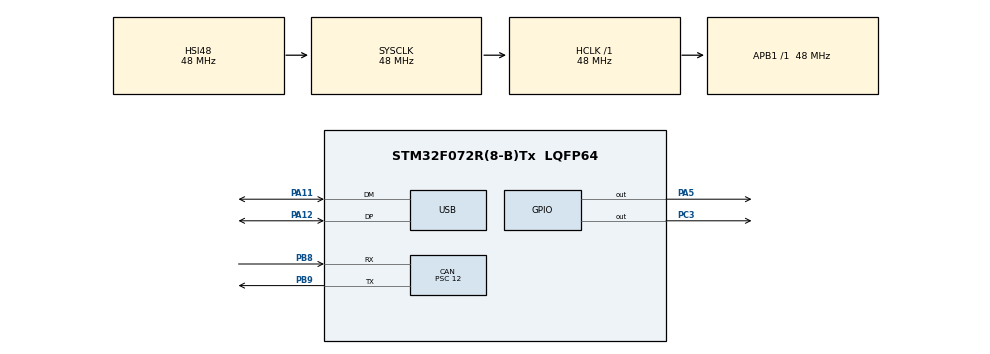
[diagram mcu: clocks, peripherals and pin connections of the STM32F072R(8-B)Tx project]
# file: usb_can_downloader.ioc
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CAN.BS1=CAN_BS1_4TQ
CAN.BS2=CAN_BS2_3TQ
CAN.CalculateTimeQuantum=250.0
CAN.Prescaler=12
Mcu.Family=STM32F0
Mcu.Name=STM32F072R(8-B)Tx
Mcu.Package=LQFP64
NVIC.CEC_CAN_IRQn=true\:0\:0\:false\:false\:true\:true\:true
NVIC.USB_IRQn=true\:0\:0\:false\:false\:true\:false\:true
PA11.Mode=Device
PA11.Signal=USB_DM
PA12.Mode=Device
PA12.Signal=USB_DP
PA13.Mode=Serial_Wire
PA13.Signal=SYS_SWDIO
PA14.Mode=Serial_Wire
PA14.Signal=SYS_SWCLK
PA5.Signal=GPIO_Output
PB8.Mode=Master
PB8.Signal=CAN_RX
PB9.Mode=Master
PB9.Signal=CAN_TX
PC3.Signal=GPIO_Output
ProjectManager.HeapSize=0x200
ProjectManager.StackSize=0x400
ProjectManager.TargetToolchain=STM32CubeIDE
RCC.AHBFreq_Value=48000000
RCC.APB1Freq_Value=48000000
RCC.APB1TimFreq_Value=48000000
RCC.HCLKFreq_Value=48000000
RCC.SYSCLKFreq_VALUE=48000000
RCC.SYSCLKSource=RCC_SYSCLKSOURCE_HSI48
USB_DEVICE.CLASS_NAME_FS=CUSTOM_HID
USB_DEVICE.MANUFACTURER_STRING=FOXLINK
USB_DEVICE.PID_CUSTOMHID_FS=22136
USB_DEVICE.PRODUCT_STRING_CUSTOMHID_FS=USB HID-TO-CAN
USB_DEVICE.USBD_CUSTOMHID_OUTREPORT_BUF_SIZE=64
USB_DEVICE.USBD_CUSTOM_HID_REPORT_DESC_SIZE=33
USB_DEVICE.VID=4660
USB_DEVICE.VirtualMode=CustomHid
USB_DEVICE.VirtualModeFS=Custom_Hid_FS
VP_USB_DEVICE_VS_USB_DEVICE_CUSTOM_HID_FS.Mode=CUSTOM_HID_FS
board=custom

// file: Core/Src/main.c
/* USER CODE BEGIN Header */
/**
  ******************************************************************************
  * @file           : main.c
  * @brief          : Main program body
  ******************************************************************************
  * @attention
  *
  * <h2><center>&copy; Copyright (c) 2019 STMicroelectronics.
  * All rights reserved.</center></h2>
  *
  * This software component is licensed by ST under BSD 3-Clause license,
  * the "License"; You may not use this file except in compliance with the
  * License. You may obtain a copy of the License at:
  *                        opensource.org/licenses/BSD-3-Clause
  *
  ******************************************************************************
  */
/* USER CODE END Header */

#include "main.h"
#include "usb_device.h"

CAN_HandleTypeDef hcan;

void SystemClock_Config(void);
static void MX_GPIO_Init(void);
static void MX_CAN_Init(void);

/* USER CODE BEGIN 0 */
uint8_t i;
/* USER CODE END 0 */

int main(void)
{

  /* MCU Configuration--------------------------------------------------------*/

  /* Reset of all peripherals, Initializes the Flash interface and the Systick. */
  HAL_Init();

  /* Configure the system clock */
  SystemClock_Config();

  /* USER CODE BEGIN SysInit */
#ifdef __DEBUG_PRINTF__
  initialise_monitor_handles();
#endif
  /* USER CODE END SysInit */

  /* Initialize all configured peripherals */
  MX_GPIO_Init();
  MX_USB_DEVICE_Init();
  MX_CAN_Init();
  /* USER CODE BEGIN 2 */
  CAN_Filter_Init();
  message_buffer_init();
  /* USER CODE END 2 */

  /* Infinite loop */
  /* USER CODE BEGIN WHILE */
  download_app();

  while (1)
  {
    /* USER CODE END WHILE */

  }
}

void SystemClock_Config(void)
{
  RCC_OscInitTypeDef RCC_OscInitStruct = {0};
  RCC_ClkInitTypeDef RCC_ClkInitStruct = {0};
  RCC_PeriphCLKInitTypeDef PeriphClkInit = {0};

  /** Initializes the CPU, AHB and APB busses clocks
  */
  RCC_OscInitStruct.OscillatorType = RCC_OSCILLATORTYPE_HSI48;
  RCC_OscInitStruct.HSI48State = RCC_HSI48_ON;
  RCC_OscInitStruct.PLL.PLLState = RCC_PLL_NONE;
  if (HAL_RCC_OscConfig(&RCC_OscInitStruct) != HAL_OK)
  {
    Error_Handler();
  }
  /** Initializes the CPU, AHB and APB busses clocks
  */
  RCC_ClkInitStruct.ClockType = RCC_CLOCKTYPE_HCLK|RCC_CLOCKTYPE_SYSCLK
                              |RCC_CLOCKTYPE_PCLK1;
  RCC_ClkInitStruct.SYSCLKSource = RCC_SYSCLKSOURCE_HSI48;
  RCC_ClkInitStruct.AHBCLKDivider = RCC_SYSCLK_DIV1;
  RCC_ClkInitStruct.APB1CLKDivider = RCC_HCLK_DIV1;

  if (HAL_RCC_ClockConfig(&RCC_ClkInitStruct, FLASH_LATENCY_1) != HAL_OK)
  {
    Error_Handler();
  }
  PeriphClkInit.PeriphClockSelection = RCC_PERIPHCLK_USB;
  PeriphClkInit.UsbClockSelection = RCC_USBCLKSOURCE_HSI48;

  if (HAL_RCCEx_PeriphCLKConfig(&PeriphClkInit) != HAL_OK)
  {
    Error_Handler();
  }
}

static void MX_CAN_Init(void)
{

  hcan.Instance = CAN;
  hcan.Init.Prescaler = 12;
  hcan.Init.Mode = CAN_MODE_NORMAL;
  hcan.Init.SyncJumpWidth = CAN_SJW_1TQ;
  hcan.Init.TimeSeg1 = CAN_BS1_4TQ;
  hcan.Init.TimeSeg2 = CAN_BS2_3TQ;
  hcan.Init.TimeTriggeredMode = DISABLE;
  hcan.Init.AutoBusOff = DISABLE;
  hcan.Init.AutoWakeUp = DISABLE;
  hcan.Init.AutoRetransmission = DISABLE;
  hcan.Init.ReceiveFifoLocked = DISABLE;
  hcan.Init.TransmitFifoPriority = DISABLE;
  if (HAL_CAN_Init(&hcan) != HAL_OK)
  {
    Error_Handler();
  }

}

static void MX_GPIO_Init(void)
{
  GPIO_InitTypeDef GPIO_InitStruct = {0};

  /* GPIO Ports Clock Enable */
  __HAL_RCC_GPIOC_CLK_ENABLE();
  __HAL_RCC_GPIOA_CLK_ENABLE();
  __HAL_RCC_GPIOB_CLK_ENABLE();

  /*Configure GPIO pin Output Level */
  HAL_GPIO_WritePin(GPIOC, GPIO_PIN_3, GPIO_PIN_RESET);

  /*Configure GPIO pin Output Level */
  HAL_GPIO_WritePin(GPIOA, GPIO_PIN_5, GPIO_PIN_RESET);

  /*Configure GPIO pin : PC3 */
  GPIO_InitStruct.Pin = GPIO_PIN_3;
  GPIO_InitStruct.Mode = GPIO_MODE_OUTPUT_PP;
  GPIO_InitStruct.Pull = GPIO_NOPULL;
  GPIO_InitStruct.Speed = GPIO_SPEED_FREQ_LOW;
  HAL_GPIO_Init(GPIOC, &GPIO_InitStruct);

  /*Configure GPIO pin : PA5 */
  GPIO_InitStruct.Pin = GPIO_PIN_5;
  GPIO_InitStruct.Mode = GPIO_MODE_OUTPUT_PP;
  GPIO_InitStruct.Pull = GPIO_NOPULL;
  GPIO_InitStruct.Speed = GPIO_SPEED_FREQ_LOW;
  HAL_GPIO_Init(GPIOA, &GPIO_InitStruct);

}

void Error_Handler(void)
{
}

/************************ (C) COPYRIGHT STMicroelectronics *****END OF FILE****/
